# cyw20829 register map
Vendor: Infineon Technologies; Series: CYW20829; File version: 1.0
CPU: CM33 r0p1, little endian, MPU, no FPU, VTOR, 3 interrupt priority bits
Registers are 32-bit, read-write, reset 0x0 unless marked. A register's access mark holds for its fields unless they carry their own. Offsets are from the block's base; [hi:lo] are bit positions; lines under a group give offsets from that group; {n}, {i} and the like mark numbered series; 'fields as' and 'values as' point back to an identical list; <NAME> marks a mode.

## PDM0 — PDM
Base 0x408D0000
0x00 CTL — Control
  [7:0] ACTIVE — Activate functionality (1 bit for each channel): '0': Reception disabled. The FIFO_OVERFLOW interrupt cause will not be activated. '1': Reception enabled. The FIFO_OVERFLOW interrupt may be activated (when an overflow event occurs). Note: This functionality is intended for startup purposes. Typically, the startup sequence is as follows: - global registers CLOCK_CTL, ROUTE_CTL, TEST_CTL, FIR*_COEFF* are initialized - One or more structures are enabled (structure specific CTL.ENABLED register field is set to '1'). - The structures are initialized (structure specific MMIO registers are written). - The structures are activated. This last step is performed by writing the CTL or CTL_SET MMIO registers, or on a rising edge ('0' to '1' transition) of a receiver's 'tr_activate' input trigger. Note: on a rising edge ('0' to '1' transition) of a receiver's 'tr_activate' input trigger, its associated CTL.ACTIVE field is set to '1'. This allows HW based synchronization of PDM receiver activation based on system triggers. Implementation note: the trigger is synchronized on the receiver clock with the receiver reset (this requires the receiver to be enabled; i.e. CTL.ENABLED is '1'). Note: if CTL_CLR.ACTIVE[i] is written to '1' at the same time a rising edge of 'tr_activate[i]' occurs, CTL.ACTIVE[i] is set to '1' (i.e. trigger takes precedence).
0x04 CTL_CLR — Control clear
  [7:0] ACTIVE — Activate functionality: '0': No effect. '1': Bit is set to '0'.
0x08 CTL_SET — Control set
  [7:0] ACTIVE — Activate functionality: '0': No effect. '1': Bit is set to '1'.
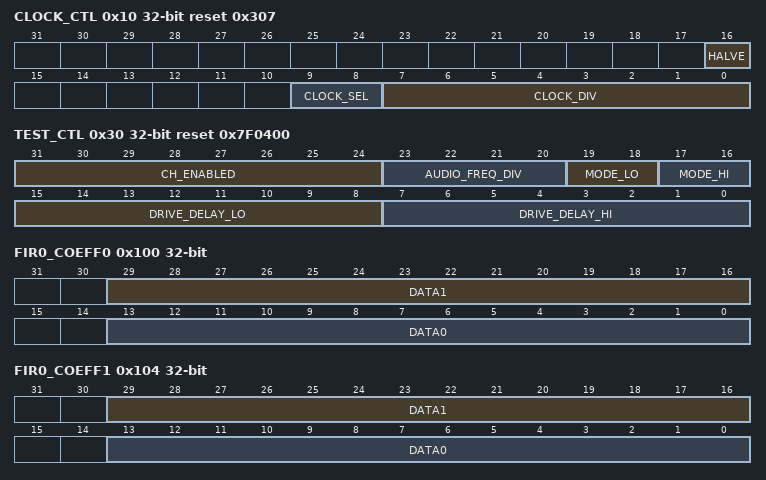
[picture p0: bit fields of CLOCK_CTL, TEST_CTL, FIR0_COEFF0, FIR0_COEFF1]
0x10 CLOCK_CTL reset 0x307 — Clock control
  [16] HALVE — Halve rate sampling: '0': Full rate sampling. The PDM interface clock pdm_clk is as specified by CLOCK_DIV[]. Each captured PDM value is provided once to the CIC filter. '1': Halve rate sampling. The PDM interface clock clk_pdm is as specified by CLOCK_DIV[] divided by two (halve the frequency). Each PDM value is captured twice and provided twice to the CIC filter; i.e. the PDM value is repeated. Note: this field is provided to dynamically change the digital microphone's clock (pdm_clk) without affecting the PDM sample frequency towards the CIC filter. Halving the microphone clock results in lower system power consumption, but does lower audio quality.
    0=FULL (N/A); 1=HALVE (N/A)
  [9:8] CLOCK_SEL — Interface clock clk_if selection: '0': SRSS clock clk_if_srss. '1': IOSS data input signal 'pdm_data[0]'. '2': IOSS data input signal 'pdm_data[1]'. '3': undefined. Note: when a data input signal is used as a clock source, it cannot be used as a data line. Note: the application is always required to program this field to a value different from the default.
    0=SEL_SRSS_CLOCK (N/A); 1=SEL_PDM_DATA0 (N/A); 2=SEL_PDM_DATA1 (N/A); 3=SEL_OR (N/A)
  [7:0] CLOCK_DIV — PDM interface clock divider (legal range [3, 255]). The PDM interface clock clk_pdm ('pdm_clk[]' output signals) is defined as pdm_clk = clk_if / (CLOCK_DIV + 1); i.e. each PDM interface clock cycle equals CLOCK_DIV + 1 clk_if clock cycles. CLOCK_DIV should be set to an odd value ([3, 5, ..., 255]), to ensure a 50/50 percent duty cycle PDM interface clock pdm_clk. '0-2': Illegal value. '3': pdm_clk frequency is 1/4 clk_if frequency (1 pdm_clk cycle consists of 4 clk_if cycles). '4': pdm_clk frequency is 1/5 clk_if frequency. Note: results in a non 50/50 percent duty cycle pdm_clk). ... '255': pdm_clk frequency is 1/256 clk_if frequency.
0x20 ROUTE_CTL — Route control
  [7:0] DATA_SEL — Specifies what IOSS data input signal 'pdm_data[]' is routed to a specific PDM receiver. Each PDM receiver j has a dedicated 1-bit control field: PDM receiver j uses DATA_SEL[j]. The 1-bit field DATA_SEL[j] specification is as follows: '0': PDM receiver j uses data input signal 'pdm_data[j]'. '1': PDM receiver j uses data input signal 'pdm_data[j ^ 1]' (the lower bit of the index is inverted). Routing the same data input signal to two PDM receivers allows for: - A single stereo digital microphone. - Two (mono) digital microphones that share a data line. E.g., if DATA_SEL is 0b00000010, PDM receivers 0 and 1 BOTH use 'pdm_data[0]'.
0x30 TEST_CTL reset 0x7F0400 — Test control
  [31:24] CH_ENABLED — Pattern generator enable (1 bit for each channel): '0' : disabled, the channel input is taken as normal from external pin pdm_data_in '1' : enabled, the channel input is taken from the pattern generator Note: the pattern generator output is routed to pdm_data_out for testing purposes Note: when all channels are disabled the pattern generator is switched off
  [23:20] AUDIO_FREQ_DIV — Frequency division factor (legal range [3, 13]) to obtain audio frequency from the PDM clock frequency. This field determines the frequency of the sine wave generated by the pattern generator when MODE=3. The formula is below: Sine wave Frequency = PDM clock frequency / 2p*2^(AUDIO_FREQ_DIV) Example: when PDM clock frequency = 3.072 MHz the audio frequencies obtained for the various values of AUDIO_FREQ_DIV are shown below: '3' : 61.115 kHz '4' : 30.558 kHz '5' : 15.279 kHz '6' : 7.639 kHz '7' : 3.820 kHz '8' : 1.910 kHz '9' : 955 Hz '10' : 477 Hz '11' : 239 Hz '12' : 119 Hz '13' : 60 Hz
    3=DIV_PDM_FREQ_BY_2PI_x_8 (Example: 3.072 MHz/(2p*8) = 61.115 kHz); 4=DIV_PDM_FREQ_BY_2PI_x_16 (Example: 3.072 MHz/(2p*16) = 30.558 kHz); 13=DIV_PDM_FREQ_BY_2PI_x_8192 (Example: 3.072 MHz/(2p*8192) = 60 Hz)
  [19:18] MODE_LO — Pattern generator mode on the low phase of the PDM interface clock. This field specifies the type of pattern driven by the generator: '0': constant 0's '1': constant 1's '2': alternating 0's and 1's (clock pattern) '3': sine wave
    0=CONSTANT_0 (N/A); 1=CONSTANT_1 (N/A); 2=ALTERNATING (N/A); 3=SINUSOID (N/A)
  [17:16] MODE_HI — Pattern generator mode on the high phase of the PDM interface clock. This field specifies the type of PDM pattern driven by the generator: '0': constant 0's '1': constant 1's '2': alternating 0's and 1's (clock pattern) '3': sinusoid
    values as MODE_LO
  [15:8] DRIVE_DELAY_LO — Interface drive delay on the low phase of the PDM interface clock. This field specifies when a PDM value is driven expressed in clk_if clock cycles. DRIVE_DELAY should be set in the range [0, IF_CTL.CLOCK_DIV]: '0': Drive PDM value 1 clk_if cycle after the rising edge of clk_pdm. '1': Drive PDM value 2 clk_if cycles after the rising edge of clk_pdm. ... '255': Drive PDM value 256 clk_if cycles after the rising edge of clk_pdm. Note: To drive on the falling edge of the PDM interface clock clk_pdm, DRIVE_DELAY should be set to IF_CTL.CLOCK_DIV/2. To drive on the rising edge of clk_pdm, DRIVE_DELAY should be set to IF_CTL.CLOCK_DIV.
  [7:0] DRIVE_DELAY_HI — Interface drive delay on the high phase of the PDM interface clock. This field specifies when a PDM value is driven expressed in clk_if clock cycles. DRIVE_DELAY should be set in the range [0, IF_CTL.CLOCK_DIV]: '0': Drive PDM value 1 clk_if cycle after the rising edge of clk_pdm. '1': Drive PDM value 2 clk_if cycles after the rising edge of clk_pdm. ... '255': Drive PDM value 256 clk_if cycles after the rising edge of clk_pdm. Note: To drive on the falling edge of the PDM interface clock clk_pdm, DRIVE_DELAY should be set to IF_CTL.CLOCK_DIV/2. To drive on the rising edge of clk_pdm, DRIVE_DELAY should be set to IF_CTL.CLOCK_DIV.
0x100 FIR0_COEFF0 reset not defined — FIR 0 coefficients 0
  [29:16] DATA1 — Filter taps 1 and 28 coefficient.
  [13:0] DATA0 — Filter taps 0 and 29 coefficient.
0x104 FIR0_COEFF1 reset not defined — FIR 0 coefficients 1
  [29:16] DATA1 — Filter taps 3 and 26 coefficient.
  [13:0] DATA0 — Filter taps 2 and 27 coefficient.
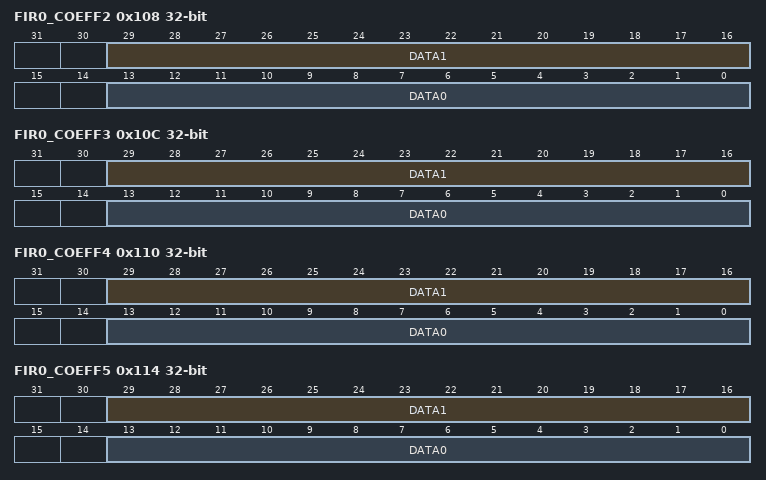
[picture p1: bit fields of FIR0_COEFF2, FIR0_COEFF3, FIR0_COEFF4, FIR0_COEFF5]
0x108 FIR0_COEFF2 reset not defined — FIR 0 coefficients 2
  [29:16] DATA1 — Filter taps 5 and 24 coefficient.
  [13:0] DATA0 — Filter taps 4 and 25 coefficient.
0x10C FIR0_COEFF3 reset not defined — FIR 0 coefficients 3
  [29:16] DATA1 — Filter taps 7 and 22 coefficient.
  [13:0] DATA0 — Filter taps 6 and 23 coefficient.
0x110 FIR0_COEFF4 reset not defined — FIR 0 coefficients 4
  [29:16] DATA1 — Filter taps 9 and 20 coefficient.
  [13:0] DATA0 — Filter taps 8 and 21 coefficient.
0x114 FIR0_COEFF5 reset not defined — FIR 0 coefficients 5
  [29:16] DATA1 — Filter taps 11 and 18 coefficient.
  [13:0] DATA0 — Filter taps 10 and 19 coefficient.
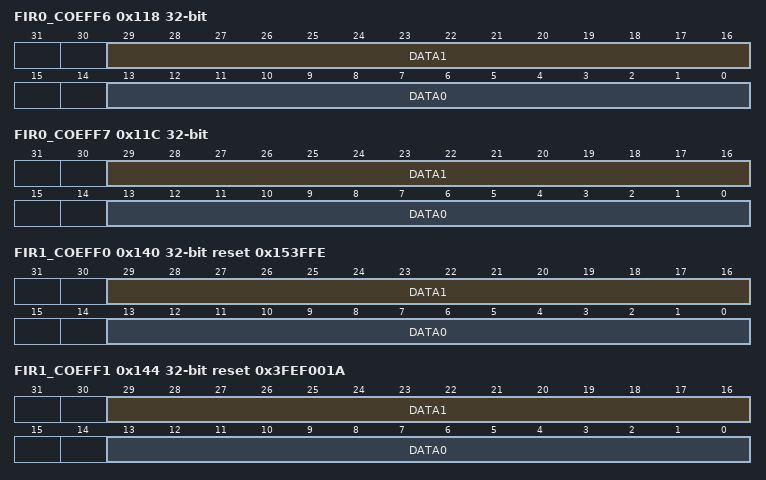
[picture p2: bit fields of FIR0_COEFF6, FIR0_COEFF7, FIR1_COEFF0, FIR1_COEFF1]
0x118 FIR0_COEFF6 reset not defined — FIR 0 coefficients 6
  [29:16] DATA1 — Filter taps 13 and 16 coefficient.
  [13:0] DATA0 — Filter taps 12 and 17 coefficient.
0x11C FIR0_COEFF7 reset not defined — FIR 0 coefficients 7
  [29:16] DATA1 — Filter tap 15 coefficient.
  [13:0] DATA0 — Filter tap 14 coefficient.
0x140 FIR1_COEFF0 reset 0x153FFE — FIR 1 coefficients 0
  [29:16] DATA1 — Filter taps 1 and 53 coefficient (default value 21).
  [13:0] DATA0 — Filter taps 0 and 54 coefficient (default value -2).
0x144 FIR1_COEFF1 reset 0x3FEF001A — FIR 1 coefficients 1
  [29:16] DATA1 — Filter taps 3 and 51 coefficient (default value -17).
  [13:0] DATA0 — Filter taps 2 and 52 coefficient (default value 26).
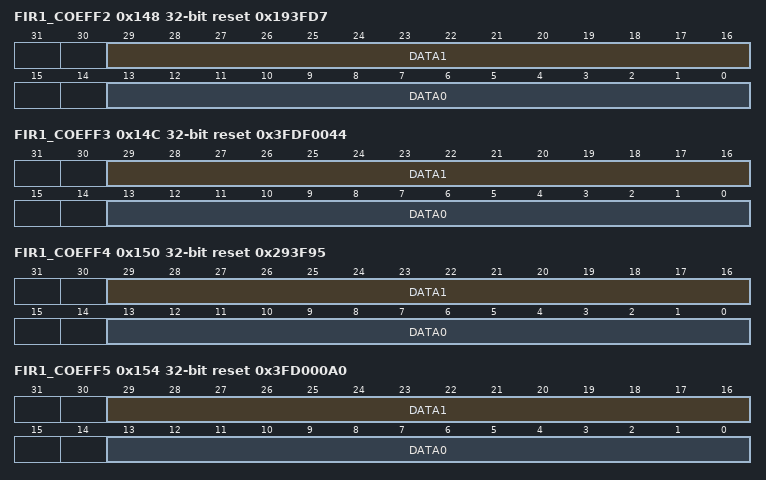
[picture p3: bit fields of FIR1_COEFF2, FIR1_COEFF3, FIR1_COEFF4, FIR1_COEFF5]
0x148 FIR1_COEFF2 reset 0x193FD7 — FIR 1 coefficients 2
  [29:16] DATA1 — Filter taps 5 and 49 coefficient (default value 25).
  [13:0] DATA0 — Filter taps 4 and 50 coefficient (default value -41).
0x14C FIR1_COEFF3 reset 0x3FDF0044 — FIR 1 coefficients 3
  [29:16] DATA1 — Filter taps 7 and 47 coefficient (default value -33).
  [13:0] DATA0 — Filter taps 6 and 48 coefficient (default value 68).
0x150 FIR1_COEFF4 reset 0x293F95 — FIR 1 coefficients 4
  [29:16] DATA1 — Filter taps 9 and 45 coefficient (default value 41).
  [13:0] DATA0 — Filter taps 8 and 46 coefficient (default value -107).
0x154 FIR1_COEFF5 reset 0x3FD000A0 — FIR 1 coefficients 5
  [29:16] DATA1 — Filter taps 11 and 43 coefficient (default value -48).
  [13:0] DATA0 — Filter taps 10 and 44 coefficient (default value 160).
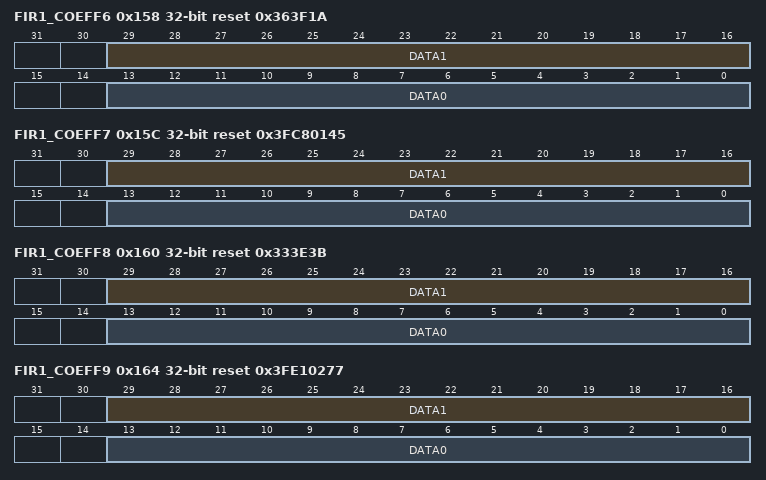
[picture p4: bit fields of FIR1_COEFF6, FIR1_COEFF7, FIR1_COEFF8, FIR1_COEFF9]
0x158 FIR1_COEFF6 reset 0x363F1A — FIR 1 coefficients 6
  [29:16] DATA1 — Filter taps 13 and 41 coefficient (default value 54).
  [13:0] DATA0 — Filter taps 12 and 42 coefficient (default value -230).
0x15C FIR1_COEFF7 reset 0x3FC80145 — FIR 1 coefficients 7
  [29:16] DATA1 — Filter taps 15 and 39 coefficient (default value -56).
  [13:0] DATA0 — Filter taps 14 and 40 coefficient (default value 325).
0x160 FIR1_COEFF8 reset 0x333E3B — FIR 1 coefficients 8
  [29:16] DATA1 — Filter taps 17 and 37 coefficient (default value 51).
  [13:0] DATA0 — Filter taps 16 and 38 coefficient (default value -453).
0x164 FIR1_COEFF9 reset 0x3FE10277 — FIR 1 coefficients 9
  [29:16] DATA1 — Filter taps 19 and 35 coefficient (default value -31).
  [13:0] DATA0 — Filter taps 18 and 36 coefficient (default value 631).
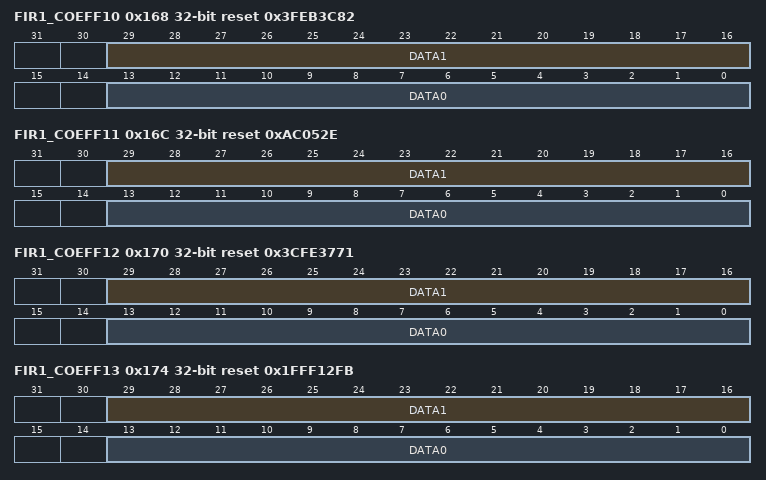
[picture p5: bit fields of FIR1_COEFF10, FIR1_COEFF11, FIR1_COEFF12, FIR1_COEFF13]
0x168 FIR1_COEFF10 reset 0x3FEB3C82 — FIR 1 coefficients 10
  [29:16] DATA1 — Filter taps 21 and 33 coefficient (default value -21).
  [13:0] DATA0 — Filter taps 20 and 34 coefficient (default value -894).
0x16C FIR1_COEFF11 reset 0xAC052E — FIR 1 coefficients 11
  [29:16] DATA1 — Filter taps 23 and 31 coefficient (default value 172).
  [13:0] DATA0 — Filter taps 22 and 32 coefficient (default value 1326).
0x170 FIR1_COEFF12 reset 0x3CFE3771 — FIR 1 coefficients 12
  [29:16] DATA1 — Filter taps 25 and 29 coefficient (default value -770).
  [13:0] DATA0 — Filter taps 24 and 30 coefficient (default value -2191).
0x174 FIR1_COEFF13 reset 0x1FFF12FB — FIR 1 coefficients 13
  [29:16] DATA1 — Filter taps 27 (center tap) coefficient (default value 8191).
  [13:0] DATA0 — Filter taps 26 and 28 coefficient (default value 4859).
{0x8000+0x100*i} CH[{i}] (i=0..1) group — PDM RX structure
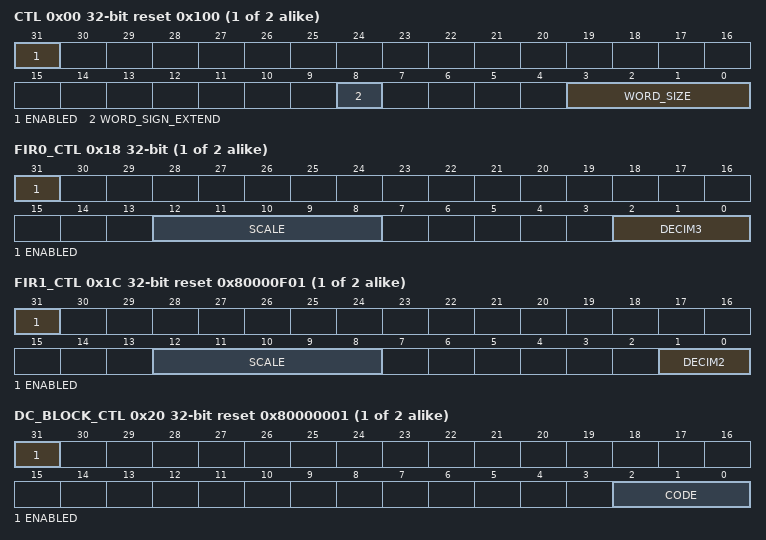
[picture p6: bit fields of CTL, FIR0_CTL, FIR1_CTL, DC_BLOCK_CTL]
  0x00 CTL reset 0x100 — Control
    [31] ENABLED — Receiver enable: '0': Disabled. If a receiver is disabled, all non-retained MMIO registers (e.g. the RX_FIFO_STATUS and INTR_RX registers) have their fields reset to their default value. '1': Enabled. Note: when all receivers are disabled, the SRAMs are driven into low power mode, if supported by the SRAM. When exiting such low power mode software needs to allow for a certain power up time before SRAM can be used, i.e. before ACTIVE can be asserted. The power up time is equivalent to the system SRAM power up time specified in the CPUSS.RAM_PWR_DELAY_CTL register.
    [8] WORD_SIGN_EXTEND — Word extension: '0': zero extension. '1': sign extension.
      0=ZERO_EXTEND (N/A); 1=SIGN_EXTEND (N/A)
    [3:0] WORD_SIZE — PCM word size: '0': 8 bit. '1': 10 bit. '2': 12 bit. '3': 14 bit. '4': 16 bit. '5': 18 bit. '6': 20 bit. '7': 24 bit. '8': 32 bit. '9'-'15': Undefined.
      0=SIZE_8 (N/A); 1=SIZE_10 (N/A); 2=SIZE_12 (N/A); 3=SIZE_14 (N/A); 4=SIZE_16 (N/A); 5=SIZE_18 (N/A); 6=SIZE_20 (N/A); 7=SIZE_24 (N/A); 8=SIZE_32 (N/A)
  0x10 IF_CTL reset 0x3 — Interface control
    [7:0] SAMPLE_DELAY — Interface sample delay. This field specifies when a PDM value is captured, expressed in clk_if clock cycles. When CLOCK_CTL.HALVE=0: '0': Capture PDM value 1 clk_if cycle after the rising edge of clk_pdm. '1': Capture PDM value 2 clk_if cycles after the rising edge of clk_pdm. ... '255': Capture PDM value 256 clk_if cycles after the rising edge of clk_pdm. When CLOCK_CTL.HALVE=1: '0': Capture PDM value 1 and 2 clk_if cycles after the rising edge of clk_pdm. '1': Capture PDM value 3 and 4 clk_if cycles after the rising edge of clk_pdm. ... '255': Capture PDM value 511 and 512 clk_if cycles after the rising edge of clk_pdm. SAMPLE_DELAY should be set such that the clk_if capture edge is at the middle point between pdm_clk_out edges. Under ideal conditions the middle point is 1/4 of the PDM interface period for the first/even/left channel, and 3/4 of the PDM interface period for the second/odd/right channel, which corresponds to the following programmings: SAMPLE_DELAY(left)=((CLOCK_DIV+1)/4) - 1 SAMPLE_DELAY(right)=(3*(CLOCK_DIV+1)/4) - 1 In practice, due to the roundtrip delay, SAMPLE_DELAY may be set to a later point with respect to the ideal middle point. Note: in all cases a SAMPLE_DELAY value that brings the capture edge close to the pdm_clk_out edges should be avoided.
  0x14 CIC_CTL reset 0x4 — CIC control
    [2:0] DECIM_CODE — CIC filter decimation. The CIC filter PCM frequency is a fraction of the PDM frequency: '0': CIC filter PCM frequency is 1/2 * PDM frequency. CIC PCM values are in the range [-0x10, 0x10]. '1': CIC filter PCM frequency is 1/4 * PDM frequency. CIC PCM values are in the range [-0x200, 0x200]. '2': CIC filter PCM frequency is 1/8 * PDM frequency. CIC PCM values are in the range [-0x4000, 0x4000]. '3': CIC filter PCM frequency is 1/16 * PDM frequency. CIC PCM values are in the range [-0x8:0000, 0x8:0000]. '4': CIC filter PCM frequency is 1/32 * PDM frequency. CIC PCM values are in the range [-0x100:0000, 0x100:0000]. '5'-'7': Illegal values. Note: The CIC filter functionality includes offsetting logic to ensure that 'digital silence' on the PDM interface (an alternating pattern of '0', '1', '0', '1' ... PDM values) results in CIC filter PCM values of '0'. Similarly, a pattern of '0', '0', '0', ... PDM values results in minimum CIC PCM value (-0x100:0000 when DECIMATION is '4') and a pattern of '1', '1', '1', ... PDM values results in maximum CIC PCM value (0x100:0000 when DECIMATION is '4'). Note: The IP's desired 'clk_sys' frequency is a function of the PDM interface clock, the CIC filter decimation (CIC_CTL.DECIM_CODE[]) and the FIR filter decimation (FIR_CTL.DECIM_CODE[]).
      0=DECIM_2 (N/A); 1=DECIM_4 (N/A); 2=DECIM_8 (N/A); 3=DECIM_16 (N/A); 4=DECIM_32 (This is the default value and the most realistic value (together with the value '3'). Typically, an overall decimation (or oversample rate (OSR)) of 64 is used, and this is achieved with the default CIC and FIR decimation values.)
  0x18 FIR0_CTL — FIR 0 control
    [31] ENABLED — FIR 0 filter coefficient enable (does NOT effect FIR filter scaling and FIR filter decimation): '0': Disabled. The middle FIR filter coefficient (16th coefficient, or tap 15 in [0:29] range) is '1' and all other FIR filter coefficients are '0'; i.e. the FIR filter is a pass through filter and the filter gain is '1'. fir0_pcm[44:0] = cic_pcm[25:0] (with sign extension) '1': Enabled. Note: This filter is disabled by default, and typically only used for sample frequencies (Fs) of 8 and 16 kHz.
    [12:8] SCALE — FIR 0 filter PCM scaling. FIR 0 filter PCM values (fir0_pcm[44:0]) are scaled (right shifted, rounded and clipped) to 26-bit signed PCM values (fir0_scaled_pcm[25:0]). These 26-bit PCM values are input to the FIR 1 filter. SCALE specifies the right shift amount (and performs a rounding): '0': fir0_scaled_pcm = CLIP26 (fir0_pcm[44:0]). '1': fir0_scaled_pcm = CLIP26 (fir0_pcm[44:1] + fir0_pcm[0]). ... '31': fir0_scaled_pcm = CLIP26 (fir0_pcm[44:31] + fir0_pcm[30]). With CLIP26(a) defined as: if (a >= 0x1ff:ffff) result = 0x1ff:ffff; else if (a < -0x200:0000) result = -0x200:0000; else result = a; Note: Clipping is not necessary for larger SCALE values, as the scaled value is guarneteed to be within the 26-bit signed integer range.
      0=N/A; 1=N/A; 31=N/A
    [2:0] DECIM3 — FIR filter decimation. The FIR filter PCM frequency is a fraction of the CIC filter PCM frequency: '0': FIR 0 filter PCM frequency is 1 * CIC filter PCM frequency. The FIR 0 filter is performed for every CIC filter PCM sample. '1': FIR 0 filter PCM frequency is 1/2 * CIC filter PCM frequency. The FIR 0 filter is performed for every second CIC filter PCM sample. '2': FIR 0 filter PCM frequency is 1/3 * CIC filter PCM frequency. The FIR 0 filter is performed for every third CIC filter PCM sample. '3': FIR 0 filter PCM frequency is 1/4 * CIC filter PCM frequency. The FIR 0 filter is performed for every fourth CIC filter PCM sample. '4': FIR 0 filter PCM frequency is 1/5 * CIC filter PCM frequency. The FIR 0 filter is performed for every fifth CIC filter PCM sample.
      {v}=DECIM_{v+1} (N/A) (v=0..4)
  0x1C FIR1_CTL reset 0x80000F01 — FIR 1 control
    [31] ENABLED — FIR 1 filter coefficient enable (does NOT effect FIR filter scaling and FIR filter decimation): '0': Disabled. The middle FIR filter coefficient (28th coefficient, or tap 27 in [0:54] range) is '1' and all other FIR filter coefficients are '0'; i.e. the FIR filter is a pass through filter and the filter gain is '1'. fir1_pcm[43:0] = fir0_scaled_pcm[25:0] (with sign extension) '1': Enabled. Note: Disabling of the filter functionality is provided for debug purposes.
    [12:8] SCALE — FIR 1 filter PCM scaling. FIR filter PCM values (fir1_pcm[43:0]) are scaled (right shifted, rounded and clipped) to 24-bit signed PCM values (fir1_scaled_pcm[23:0]). These 24-bit PCM values are input to the DC blocker. SCALE specifies the right shift amount (and performs a rounding): '0': fir1_scaled_pcm = CLIP24 (fir1_pcm[43:0]). '1': fir1_scaled_pcm = CLIP24 (fir1_pcm[43:1] + fir1_pcm[0]). ... '31': fir1_scaled_pcm = CLIP24 (fir1_pcm[43:31] + fir1_pcm[30]). With CLIP24(a) defined as: if (a >= 0x7f:ffff) result = 0x7f:ffff; else if (a < -0x80:0000) result = -0x80:0000; else result = a; Note: Clipping is not necessary for larger SCALE values, as the scaled value is guarneteed to be within the 24-bit signed integer range.
      0=N/A; 1=N/A; 31=N/A
    [1:0] DECIM2 — FIR 1 filter decimation. The FIR filter PCM frequency is a fraction of the FIR0 filter PCM frequency: '0': FIR 1 filter PCM frequency is 1 * FIR 0 filter PCM frequency. The FIR filter is performed for every FIR 0 filter PCM sample. '1': FIR 1 filter PCM frequency is 1/2 * FIR 0 filter PCM frequency. The FIR filter is performed for every second FIR 0 filter PCM sample. '2': FIR 1 filter PCM frequency is 1/3 * FIR 0 filter PCM frequency. The FIR filter is performed for every third FIR 0 filter PCM sample. '3': FIR 1 filter PCM frequency is 1/4 * FIR 0 filter PCM frequency. The FIR filter is performed for every fourth FIR 0 filter PCM sample.
      {v}=DECIM_{v+1} (N/A) (v=0..3)
  0x20 DC_BLOCK_CTL reset 0x80000001 — DC block control
    [31] ENABLED — DC blocker enable: '0': Disabled. The functionality is defined as: dc_block_pcm(n) = fir1_scaled_pcm(n) '1': Enabled. The functionality is as specified by the CODE field. Note: disabling of the DC blocker filter functionality is provided for debug purposes.
    [2:0] CODE — DC blocker coefficient. The DC blocker is defined as: dc_block_state_scaled(n-1) = dc_block_state(n-1) - (dc_block_state(n-1) >> (12-CODE)) dc_block_state(n) = CLIP37 ( 2^13 * (fir1_scaled_pcm(n) - fir1_scaled_pcm(n-1)) + dc_block_state_scaled(n-1)) dc_block_pcm(n) = dc_block_state(n) >> 13 This first step is a scaling step of the DC block state. It effectively multiplies the DC block state with a variable 'alpha' that is close to '1': '0': alpha = 1 - (1/2^(12-0)) = 0.999755859. '1': alpha = 1 - (1/2^(12-1)) = 0.999511719. '2': alpha = 1 - (1/2^(12-2)) = 0.999023438. '3': alpha = 1 - (1/2^(12-3)) = 0.998046875. '4': alpha = 1 - (1/2^(12-4)) = 0.99609375. '5': alpha = 1 - (1/2^(12-5)) = 0.9921875. '6': alpha = 1 - (1/2^(12-6)) = 0.984375. '7': alpha = 1 - (1/2^(12-7)) = 0.96875.
      {v}=N/A (v=0..7)
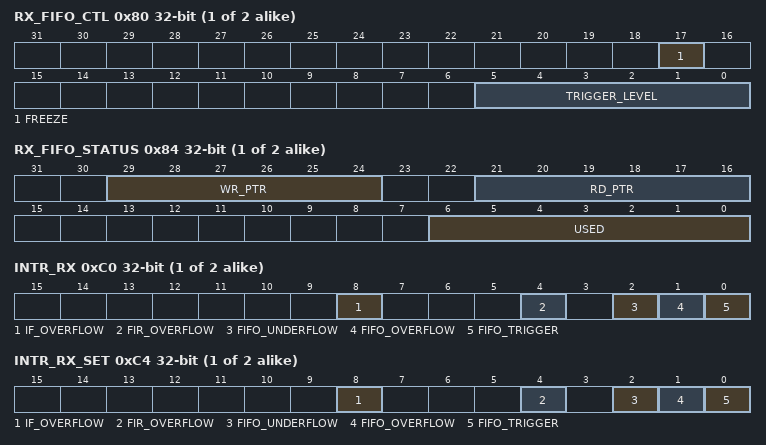
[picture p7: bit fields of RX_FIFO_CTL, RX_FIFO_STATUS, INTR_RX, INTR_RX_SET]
  0x80 RX_FIFO_CTL — RX FIFO control
    [17] FREEZE — Freeze functionality: '0': HW writes to the RX FIFO and advances the FIFO write pointer. '1': HW writes from the RX FIFO have no effect: freeze will not advance the FIFO write pointer. Note: This functionality is intended for debugging purposes.
    [5:0] TRIGGER_LEVEL — Trigger level. When the RX FIFO has more entries than the number of this field, a receiver trigger event is generated: - INTR_RX.FIFO_TRIGGER = (# FIFO entries > TRIGGER_LEVEL)
      0=EMPTY (N/A); 1=USED_1 (N/A); 63=USED_63 (N/A)
  0x84 RX_FIFO_STATUS ro
    [29:24] WR_PTR — RX FIFO write pointer: FIFO location at which a new data is written by the hardware. Note: This functionality is intended for debugging purposes.
    [21:16] RD_PTR — RX FIFO read pointer: FIFO location from which a data is read. Note: This functionality is intended for debugging purposes.
    [6:0] USED — Number of used/occupied entries in the RX FIFO. The field value is in the range [0, 64]. When '0', the FIFO is empty. When '64', the FIFO is full.
  0x88 RX_FIFO_RD ro — RX FIFO read
    [31:0] DATA — Data (PCM sample) read from the RX FIFO. Reading removes the data from the RX FIFO; i.e. behavior is similar to that of a POP operation (RX_FIFO_STATUS.RD_PTR is incremented and RX_FIFO_STATUS.USED is decremented). The read data (DATA) is right aligned (unused bit positions follow the specified sign extension per CTL.WORD_SIGN_EXTEND) when it is read from the FIFO entry (data[23:0]): - 8 bit, DATA[7:0] = data[23:16]. - 10 bit, DATA[9:0] = data[23:14]. - 12 bit, DATA[11:0] = data[23:12]. - 14 bit, DATA[13:0] = data[23:10]. - 16 bit, DATA[15:0] = data[23:8]. - 18 bit, DATA[17:0] = data[23:6]. - 20 bit, DATA[19:0] = data[23:4]. - 24 bit, DATA[23:0] = data[23:0]. - 32 bit, DATA[31:0] = data[23:0] << 8. Note: Reading from an empty RX FIFO activates INTR_RX.FIFO_UNDERFLOW.
  0x8C RX_FIFO_RD_SILENT ro — RX FIFO silent read
    [31:0] DATA — Data (PCM sample) read from the RX FIFO. Reading will NOT remove the data from the RX FIFO; i.e. behavior is similar to that of a PEEK operation. See RX_FIFO_RD for data alignment. Note: Reading from an empty RX FIFO activates INTR.RX_FIFO_UNDERFLOW (the read returns 0xffff:ffff). Note: This functionality is intended for debugging purposes.
  0xC0 INTR_RX — Interrupt
    [8] IF_OVERFLOW — HW sets this field to '1', when PDM samples are generated too fast by the interface logic (interface overflow). This may be an indication that the IP system frequency is too low wrt. the interface frequency (a SW configuration error). The interface overflow is a non-recoverable error and requires SW disabling (CTL.ENABLED) of the receiver clearing INTR_RX.IF_OVERFLOW to '0' does not resolve the interface underflow). Note: This functionality is intended for debug purposes.
    [4] FIR_OVERFLOW — HW sets this field to '1', when CIC filter PCM samples are produced at a faster rate than the FIR filter can process them. This is an indication that the IP system frequency is too low. Note: This functionality is intended for debugging purposes.
    [2] FIFO_UNDERFLOW — HW sets this field to '1', when reading from an empty RX FIFO (RX_FIFO_STATUS.USED is '0').
    [1] FIFO_OVERFLOW — HW sets this field to '1', when writing to a full RX FIFO (RX_FIFO_STATUS.USED is '64').
    [0] FIFO_TRIGGER — HW sets this field to '1', when a RX trigger is generated.
  0xC4 INTR_RX_SET — Interrupt set
    [8] IF_OVERFLOW — Write this field with '1' to set corresponding INTR_RX field (a write of '0' has no effect).
    [4] FIR_OVERFLOW — Write this field with '1' to set corresponding INTR_RX field (a write of '0' has no effect).
    [2] FIFO_UNDERFLOW — Write this field with '1' to set corresponding INTR_RX field (a write of '0' has no effect).
    [1] FIFO_OVERFLOW — Write this field with '1' to set corresponding INTR_RX field (a write of '0' has no effect).
    [0] FIFO_TRIGGER — Write this field with '1' to set corresponding INTR_RX field (a write of '0' has no effect).
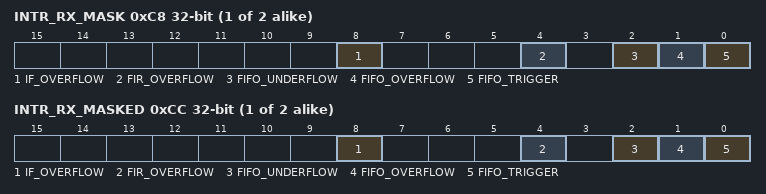
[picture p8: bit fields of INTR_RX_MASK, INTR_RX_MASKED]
  0xC8 INTR_RX_MASK — Interrupt mask
    [8] IF_OVERFLOW — Mask for corresponding field in INTR_RX register.
    [4] FIR_OVERFLOW — Mask for corresponding field in INTR_RX register.
    [2] FIFO_UNDERFLOW — Mask for corresponding field in INTR_RX register.
    [1] FIFO_OVERFLOW — Mask for corresponding field in INTR_RX register.
    [0] FIFO_TRIGGER — Mask for corresponding field in INTR_RX register.
  0xCC INTR_RX_MASKED ro — Interrupt masked
    [8] IF_OVERFLOW — Logical AND of corresponding INTR_RX and INTR_RX_MASK fields.
    [4] FIR_OVERFLOW — Logical AND of corresponding INTR_RX and INTR_RX_MASK fields.
    [2] FIFO_UNDERFLOW — Logical AND of corresponding INTR_RX and INTR_RX_MASK fields.
    [1] FIFO_OVERFLOW — Logical AND of corresponding INTR_RX and INTR_RX_MASK fields.
    [0] FIFO_TRIGGER — Logical AND of corresponding INTR_RX and INTR_RX_MASK fields.
